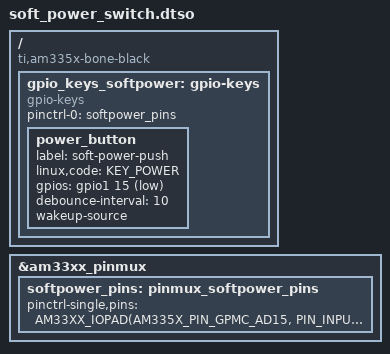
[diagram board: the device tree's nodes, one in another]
/dts-v1/;
/plugin/;

#include <dt-bindings/gpio/gpio.h>
#include <dt-bindings/input/input.h>
#include <dt-bindings/pinctrl/am33xx.h>

/ {
    compatible = "ti,am335x-bone-black", "ti,am335x-bone";

    fragment@0 {
        target = <&am33xx_pinmux>;
        __overlay__ {
            softpower_pins: pinmux_softpower_pins {
                pinctrl-single,pins = <
                    /* P8_15 = gpio1_15 : PUSH */
                    AM33XX_IOPAD(AM335X_PIN_GPMC_AD15, PIN_INPUT_PULLUP | MUX_MODE7)

                    /* P8_16 = gpio1_14 : OFF */
                    AM33XX_IOPAD(AM335X_PIN_GPMC_AD14, PIN_OUTPUT_PULLDOWN | MUX_MODE7)
                >;
            };
        };
    };

    fragment@1 {
        target-path = "/";
        __overlay__ {
            gpio_keys_softpower: gpio-keys {
                compatible = "gpio-keys";
                pinctrl-names = "default";
                pinctrl-0 = <&softpower_pins>;
                status = "okay";

                power_button {
                    label = "soft-power-push";
                    linux,code = <KEY_POWER>;
                    gpios = <&gpio1 15 GPIO_ACTIVE_LOW>;
                    debounce-interval = <10>;
                    wakeup-source;
                };
            };
        };
    };
};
